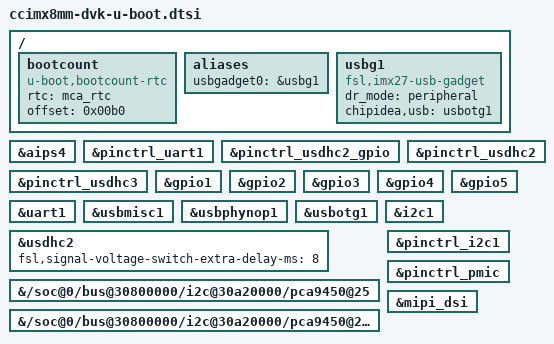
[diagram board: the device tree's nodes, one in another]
// SPDX-License-Identifier: GPL-2.0+
/*
 * Copyright 2021-2025 Digi International Inc.
 */

#include "imx8mm-u-boot.dtsi"

/{
	bootcount {
		compatible = "u-boot,bootcount-rtc";
		rtc = <&mca_rtc>;
		offset = <0x00b0>;
	};

	aliases {
		usbgadget0 = &usbg1;
	};

	usbg1: usbg1 {
		compatible = "fsl,imx27-usb-gadget";
		dr_mode = "peripheral";
		chipidea,usb = <&usbotg1>;
		status = "okay";
	};
};

&aips4 {
	bootph-pre-ram;
};

&pinctrl_uart1 {
	bootph-pre-ram;
};

&pinctrl_usdhc2_gpio {
	bootph-pre-ram;
};

&pinctrl_usdhc2 {
	bootph-pre-ram;
};

&pinctrl_usdhc3 {
	bootph-pre-ram;
};

&gpio1 {
	bootph-pre-ram;
};

&gpio2 {
	bootph-pre-ram;
};

&gpio3 {
	bootph-pre-ram;
};

&gpio4 {
	bootph-pre-ram;
};

&gpio5 {
	bootph-pre-ram;
};

&uart1 {
	bootph-pre-ram;
};

&usbmisc1 {
	bootph-pre-ram;
};

&usbphynop1 {
	bootph-pre-ram;
};

&usbotg1 {
	bootph-pre-ram;
};

&usdhc2 {
	bootph-pre-ram;
	fsl,signal-voltage-switch-extra-delay-ms = <8>;
};

&i2c1 {
	bootph-pre-ram;
};

&{/soc@0/bus@30800000/i2c@30a20000/pca9450@25} {
	bootph-pre-ram;
};

&{/soc@0/bus@30800000/i2c@30a20000/pca9450@25/regulators} {
	bootph-pre-ram;
};

&pinctrl_i2c1 {
	bootph-pre-ram;
};

&pinctrl_pmic {
	bootph-pre-ram;
};

&mipi_dsi {
	/delete-property/ assigned-clocks;
	/delete-property/ assigned-clock-parents;
	/delete-property/ assigned-clock-rates;
};
